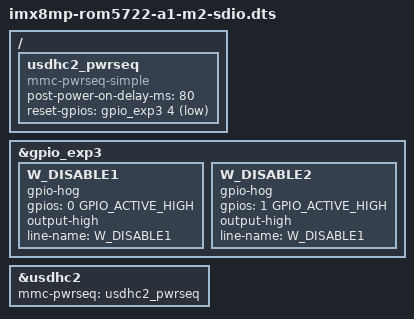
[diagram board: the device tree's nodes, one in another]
// SPDX-License-Identifier: (GPL-2.0+ OR MIT)
/*
 * Copyright 2019 NXP
 */
#include "imx8mp-rom5722-a1.dts"

/ {
	usdhc2_pwrseq: usdhc2_pwrseq {
                compatible = "mmc-pwrseq-simple";
                post-power-on-delay-ms = <80>;
                reset-gpios =   <&gpio_exp3 4 GPIO_ACTIVE_LOW>;
        };
};

&gpio_exp3 {
	W_DISABLE1 {
		gpio-hog;
		gpios = <0 GPIO_ACTIVE_HIGH>;
		output-high;
		line-name = "W_DISABLE1";
	};
	W_DISABLE2 {
		gpio-hog;
		gpios = <1 GPIO_ACTIVE_HIGH>;
		output-high;
		line-name = "W_DISABLE1";
	};
};

&usdhc2 {
	/delete-property/cd-gpios;
	/delete-property/wp-gpios;
	/delete-property/ vmmc-supply;
        mmc-pwrseq = <&usdhc2_pwrseq>;
};
